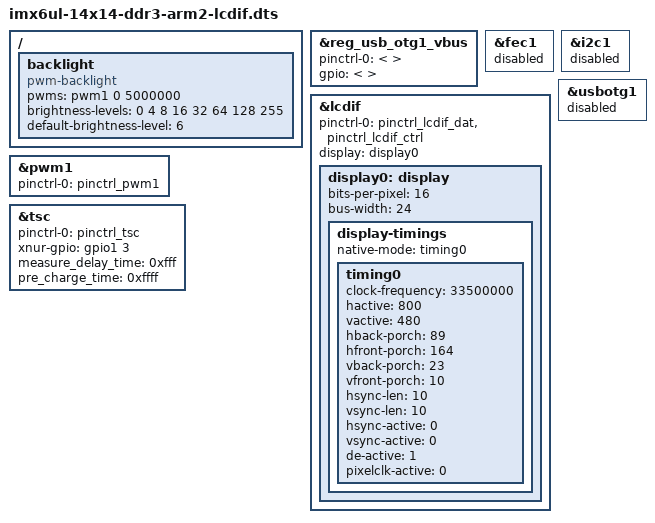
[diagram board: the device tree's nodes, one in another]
/*
 * Copyright (C) 2015 Freescale Semiconductor, Inc.
 *
 * This program is free software; you can redistribute it and/or modify
 * it under the terms of the GNU General Public License version 2 as
 * published by the Free Software Foundation.
 */

#include "imx6ul-14x14-ddr3-arm2.dts"

/ {
	backlight {
		compatible = "pwm-backlight";
		pwms = <&pwm1 0 5000000>;
		brightness-levels = <0 4 8 16 32 64 128 255>;
		default-brightness-level = <6>;
		status = "okay";
	};
};

&reg_usb_otg1_vbus {
	pinctrl-0 = < >;
	gpio = < >;
};

&fec1{
       status = "disabled";
};

&lcdif {
	pinctrl-names = "default";
	pinctrl-0 = <&pinctrl_lcdif_dat
		     &pinctrl_lcdif_ctrl>;
	display = <&display0>;
	status = "okay";

	display0: display {
		bits-per-pixel = <16>;
		bus-width = <24>;

		display-timings {
			native-mode = <&timing0>;
			timing0: timing0 {
				clock-frequency = <33500000>;
				hactive = <800>;
				vactive = <480>;
				hback-porch = <89>;
				hfront-porch = <164>;
				vback-porch = <23>;
				vfront-porch = <10>;
				hsync-len = <10>;
				vsync-len = <10>;
				hsync-active = <0>;
				vsync-active = <0>;
				de-active = <1>;
				pixelclk-active = <0>;
			};
		};
	};
};

&pwm1 {
	pinctrl-names = "default";
	pinctrl-0 = <&pinctrl_pwm1>;
	status = "okay";
};

&i2c1 {
	status = "disabled";
};

&usbotg1 {
	status = "disabled";
};

&tsc {
	pinctrl-names = "default";
	pinctrl-0 = <&pinctrl_tsc>;
	status = "okay";
	xnur-gpio = <&gpio1 3 0>;
	measure_delay_time = <0xfff>;
	pre_charge_time = <0xffff>;
};
